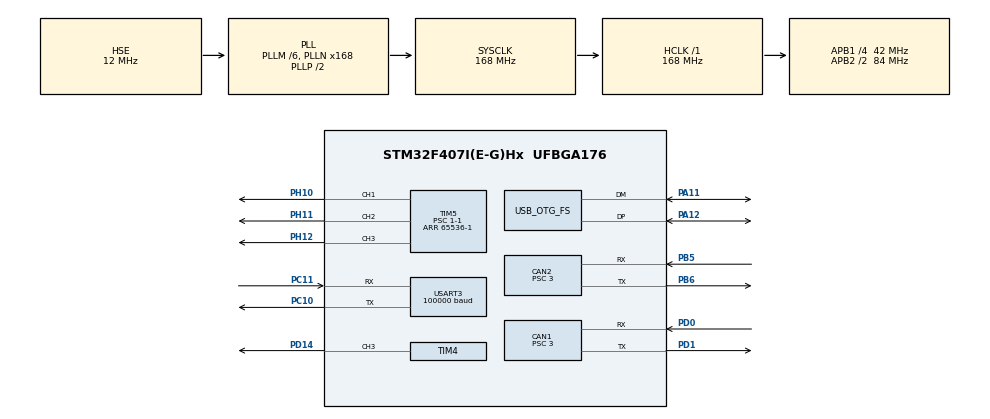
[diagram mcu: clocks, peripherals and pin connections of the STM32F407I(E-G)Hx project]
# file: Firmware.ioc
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CAN1.ABOM=ENABLE
CAN1.BS1=CAN_BS1_10TQ
CAN1.BS2=CAN_BS2_3TQ
CAN1.CalculateBaudRate=1000000
CAN1.CalculateTimeBit=1000
CAN1.CalculateTimeQuantum=71.42857142857143
CAN1.NART=ENABLE
CAN1.Prescaler=3
CAN2.ABOM=ENABLE
CAN2.BS1=CAN_BS1_10TQ
CAN2.BS2=CAN_BS2_3TQ
CAN2.CalculateBaudRate=1000000
CAN2.CalculateTimeBit=1000
CAN2.CalculateTimeQuantum=71.42857142857143
CAN2.NART=ENABLE
CAN2.Prescaler=3
Dma.Request0=USART3_RX
Dma.USART3_RX.0.Direction=DMA_PERIPH_TO_MEMORY
Dma.USART3_RX.0.FIFOMode=DMA_FIFOMODE_DISABLE
Dma.USART3_RX.0.Instance=DMA1_Stream1
Dma.USART3_RX.0.MemDataAlignment=DMA_MDATAALIGN_BYTE
Dma.USART3_RX.0.MemInc=DMA_MINC_ENABLE
Dma.USART3_RX.0.Mode=DMA_NORMAL
Dma.USART3_RX.0.PeriphDataAlignment=DMA_PDATAALIGN_BYTE
Dma.USART3_RX.0.PeriphInc=DMA_PINC_DISABLE
Dma.USART3_RX.0.Priority=DMA_PRIORITY_LOW
Mcu.Family=STM32F4
Mcu.Name=STM32F407I(E-G)Hx
Mcu.Package=UFBGA176
NVIC.CAN1_RX0_IRQn=true\:5\:0\:true\:false\:true\:true\:true\:true
NVIC.CAN2_RX0_IRQn=true\:5\:0\:true\:false\:true\:true\:true\:true
NVIC.DMA1_Stream1_IRQn=true\:5\:0\:true\:false\:true\:false\:true\:true
NVIC.OTG_FS_IRQn=true\:5\:0\:true\:false\:true\:false\:true\:true
NVIC.PriorityGroup=NVIC_PRIORITYGROUP_4
NVIC.USART3_IRQn=true\:5\:0\:true\:false\:true\:true\:true\:true
PA11.Mode=Device_Only
PA11.Signal=USB_OTG_FS_DM
PA12.Mode=Device_Only
PA12.Signal=USB_OTG_FS_DP
PA13.Mode=Serial_Wire
PA13.Signal=SYS_JTMS-SWDIO
PA14.Mode=Serial_Wire
PA14.Signal=SYS_JTCK-SWCLK
PB5.Mode=CAN_Activate
PB5.Signal=CAN2_RX
PB6.Mode=CAN_Activate
PB6.Signal=CAN2_TX
PC10.Mode=Asynchronous
PC10.Signal=USART3_TX
PC11.Mode=Asynchronous
PC11.Signal=USART3_RX
PD0.Mode=CAN_Activate
PD0.Signal=CAN1_RX
PD1.Mode=CAN_Activate
PD1.Signal=CAN1_TX
PD14.Signal=S_TIM4_CH3
PH0-OSC_IN.Mode=HSE-External-Oscillator
PH0-OSC_IN.Signal=RCC_OSC_IN
PH1-OSC_OUT.Mode=HSE-External-Oscillator
PH1-OSC_OUT.Signal=RCC_OSC_OUT
PH10.Signal=S_TIM5_CH1
PH11.Signal=S_TIM5_CH2
PH12.Signal=S_TIM5_CH3
ProjectManager.HeapSize=0x200
ProjectManager.StackSize=0x400
ProjectManager.TargetToolchain=CMake
RCC.48MHZClocksFreq_Value=48000000
RCC.AHBFreq_Value=168000000
RCC.APB1CLKDivider=RCC_HCLK_DIV4
RCC.APB1Freq_Value=42000000
RCC.APB1TimFreq_Value=84000000
RCC.APB2CLKDivider=RCC_HCLK_DIV2
RCC.APB2Freq_Value=84000000
RCC.APB2TimFreq_Value=168000000
RCC.CortexFreq_Value=168000000
RCC.HCLKFreq_Value=168000000
RCC.HSE_VALUE=12000000
RCC.HSI_VALUE=16000000
RCC.LSE_VALUE=32768
RCC.PLLM=6
RCC.PLLN=168
RCC.PLLQ=7
RCC.SYSCLKFreq_VALUE=168000000
RCC.SYSCLKSource=RCC_SYSCLKSOURCE_PLLCLK
RCC.VCOOutputFreq_Value=336000000
SH.S_TIM4_CH3.0=TIM4_CH3,PWM Generation3 CH3
SH.S_TIM5_CH1.0=TIM5_CH1,PWM Generation1 CH1
SH.S_TIM5_CH2.0=TIM5_CH2,PWM Generation2 CH2
SH.S_TIM5_CH3.0=TIM5_CH3,PWM Generation3 CH3
TIM4.Channel-PWM\ Generation3\ CH3=TIM_CHANNEL_3
TIM4.Period=21000-1
TIM5.Channel-PWM\ Generation1\ CH1=TIM_CHANNEL_1
TIM5.Channel-PWM\ Generation2\ CH2=TIM_CHANNEL_2
TIM5.Channel-PWM\ Generation3\ CH3=TIM_CHANNEL_3
TIM5.Period=65536-1
TIM5.Prescaler=1-1
USART3.BaudRate=100000
USART3.Parity=PARITY_EVEN
USART3.VirtualMode=VM_ASYNC
USART3.WordLength=WORDLENGTH_9B
USB_DEVICE.CLASS_NAME_FS=CDC
USB_DEVICE.PID_CDC_FS=202
USB_DEVICE.PRODUCT_STRING_CDC_FS=Vision Comm Port
USB_DEVICE.VirtualMode-CDC_FS=Cdc
USB_DEVICE.VirtualModeFS=Cdc_FS
USB_OTG_FS.VirtualMode=Device_Only
VP_USB_DEVICE_VS_USB_DEVICE_CDC_FS.Mode=CDC_FS
board=custom

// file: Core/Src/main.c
/* USER CODE BEGIN Header */
/**
  ******************************************************************************
  * @file           : main.c
  * @brief          : Main program body
  ******************************************************************************
  * @attention
  *
  * Copyright (c) 2026 STMicroelectronics.
  * All rights reserved.
  *
  * This software is licensed under terms that can be found in the LICENSE file
  * in the root directory of this software component.
  * If no LICENSE file comes with this software, it is provided AS-IS.
  *
  ******************************************************************************
  */
/* USER CODE END Header */
#include "main.h"
#include "can.h"
#include "dma.h"
#include "tim.h"
#include "usart.h"
#include "usb_device.h"
#include "gpio.h"

/* USER CODE BEGIN Includes */
#include "robot.h"
#include "robot_config.h"
#include "bsp_usb.h"
/* USER CODE END Includes */

void SystemClock_Config(void);

int main(void)
{

  /* MCU Configuration--------------------------------------------------------*/

  /* Reset of all peripherals, Initializes the Flash interface and the Systick. */
  HAL_Init();

  /* USER CODE BEGIN Init */
  /* A debugger (OpenOCD reset-init) or bootloader may leave the PLL running as SYSCLK,
     which makes HAL_RCC_OscConfig() refuse to reconfigure it. Start from the reset state. */
  HAL_RCC_DeInit();
  /* USER CODE END Init */

  /* Configure the system clock */
  SystemClock_Config();

  /* USER CODE BEGIN SysInit */
  /* Must run before MX_USB_DEVICE_Init: makes the PC re-detect the board after flash/reset. */
  BSP_USB_ForceReenumerate();
  /* USER CODE END SysInit */

  /* Initialize all configured peripherals */
  MX_GPIO_Init();
  MX_DMA_Init();
  MX_TIM5_Init();
  MX_TIM4_Init();
  MX_CAN1_Init();
  MX_CAN2_Init();
  MX_USART3_UART_Init();
  MX_USB_DEVICE_Init();
  /* USER CODE BEGIN 2 */
  // HAL_TIM_Base_Init(&htim4);
  // HAL_TIM_PWM_Start(&htim4, TIM_CHANNEL_3);
  // HAL_TIM_PWM_Start(&htim5, TIM_CHANNEL_1);
  // HAL_TIM_PWM_Start(&htim5, TIM_CHANNEL_2);
  // HAL_TIM_PWM_Start(&htim5, TIM_CHANNEL_3);
  HAL_Delay(500); /* let the ESCs and the receiver power up */
  Robot_Init();
  /* USER CODE END 2 */

  /* Infinite loop */
  /* USER CODE BEGIN WHILE */
  while (1)
  {
    Robot_Task(ROBOT_TASK_PERIOD_S);
    HAL_Delay(1); /* waits 1..2 ms: the loop runs about every 2 ms (see ROBOT_TASK_PERIOD_S) */
    /* USER CODE END WHILE */

  }
}

void SystemClock_Config(void)
{
  RCC_OscInitTypeDef RCC_OscInitStruct = {0};
  RCC_ClkInitTypeDef RCC_ClkInitStruct = {0};

  /** Configure the main internal regulator output voltage
  */
  __HAL_RCC_PWR_CLK_ENABLE();
  __HAL_PWR_VOLTAGESCALING_CONFIG(PWR_REGULATOR_VOLTAGE_SCALE1);

  /** Initializes the RCC Oscillators according to the specified parameters
  * in the RCC_OscInitTypeDef structure.
  */
  RCC_OscInitStruct.OscillatorType = RCC_OSCILLATORTYPE_HSE;
  RCC_OscInitStruct.HSEState = RCC_HSE_ON;
  RCC_OscInitStruct.PLL.PLLState = RCC_PLL_ON;
  RCC_OscInitStruct.PLL.PLLSource = RCC_PLLSOURCE_HSE;
  RCC_OscInitStruct.PLL.PLLM = 6;
  RCC_OscInitStruct.PLL.PLLN = 168;
  RCC_OscInitStruct.PLL.PLLP = RCC_PLLP_DIV2;
  RCC_OscInitStruct.PLL.PLLQ = 7;
  if (HAL_RCC_OscConfig(&RCC_OscInitStruct) != HAL_OK)
  {
    Error_Handler();
  }

  /** Initializes the CPU, AHB and APB buses clocks
  */
  RCC_ClkInitStruct.ClockType = RCC_CLOCKTYPE_HCLK|RCC_CLOCKTYPE_SYSCLK
                              |RCC_CLOCKTYPE_PCLK1|RCC_CLOCKTYPE_PCLK2;
  RCC_ClkInitStruct.SYSCLKSource = RCC_SYSCLKSOURCE_PLLCLK;
  RCC_ClkInitStruct.AHBCLKDivider = RCC_SYSCLK_DIV1;
  RCC_ClkInitStruct.APB1CLKDivider = RCC_HCLK_DIV4;
  RCC_ClkInitStruct.APB2CLKDivider = RCC_HCLK_DIV2;

  if (HAL_RCC_ClockConfig(&RCC_ClkInitStruct, FLASH_LATENCY_5) != HAL_OK)
  {
    Error_Handler();
  }
}

void Error_Handler(void)
{
  __disable_irq();
  while (1)
  {
  }
}
